# MKW38A4 register map
Vendor: NXP Semiconductors; Series: Kinetis_W; File version: 1.6
CPU: CM0PLUS r0p0, little endian, no MPU, no FPU, VTOR, 2 interrupt priority bits
Registers are 32-bit, read-write, no defined reset value unless marked. A register's access mark holds for its fields unless they carry their own. Offsets are from the block's base; [hi:lo] are bit positions; {n}, {i} and the like mark numbered series.

## GENFSK — GENERIC FSK
Base 0x40082000
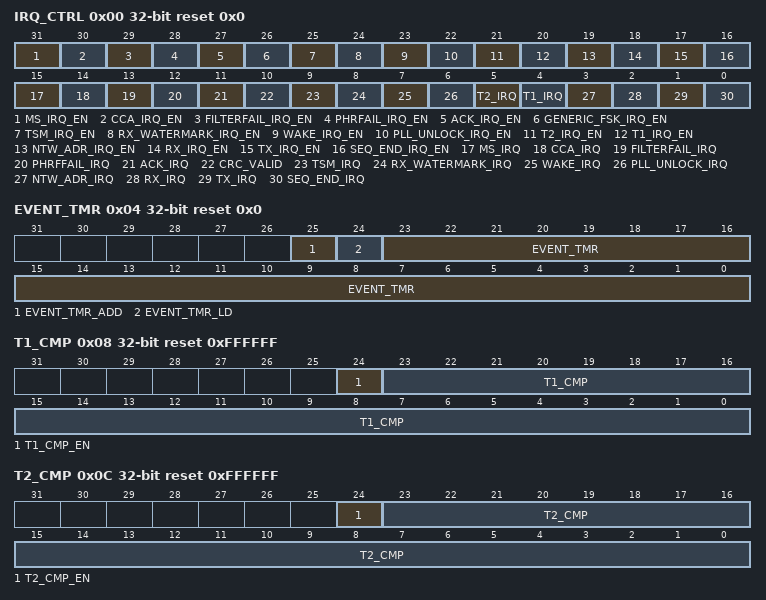
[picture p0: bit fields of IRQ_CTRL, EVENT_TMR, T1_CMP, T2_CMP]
0x00 IRQ_CTRL reset 0x0 — IRQ CONTROL
  [31] MS_IRQ_EN — MS_IRQ Enable
    0=MS Interrupt is not enabled; 1=MS Interrupt is enabled
  [30] CCA_IRQ_EN — CCA_IRQ Enable
    0=CCA Interrupt is not enabled; 1=CCA Interrupt is enabled
  [29] FILTERFAIL_IRQ_EN — FILTERFAIL_IRQ Enable
    0=FILTERFAIL Interrupt is not enabled; 1=FILTERFAIL Interrupt is enabled
  [28] PHRFAIL_IRQ_EN — PHRFAIL_IRQ Enable
    0=PHRFAIL Interrupt is not enabled; 1=PHRFAIL Interrupt is enabled
  [27] ACK_IRQ_EN — ACK_IRQ Enable
    0=Auto ACK Interrupt is not enabled; 1=Auto ACK Interrupt is enabled
  [26] GENERIC_FSK_IRQ_EN — GENERIC_FSK_IRQ Master Enable
    0=All GENERIC_FSK Interrupts are disabled; 1=All GENERIC_FSK Interrupts can be enabled
  [25] TSM_IRQ_EN — TSM_IRQ Enable
    0=TSM Interrupt is not enabled; 1=TSM Interrupt is enabled
  [24] RX_WATERMARK_IRQ_EN — RX_WATERMARK_IRQ Enable
    0=RX Watermark Interrupt is not enabled; 1=RX Watermark Interrupt is enabled
  [23] WAKE_IRQ_EN — WAKE_IRQ Enable
    0=Wake Interrupt is not enabled; 1=Wake Interrupt is enabled
  [22] PLL_UNLOCK_IRQ_EN — PLL_UNLOCK_IRQ Enable
    0=PLL Unlock Interrupt is not enabled; 1=PLL Unlock Interrupt is enabled
  [21] T2_IRQ_EN — T2_IRQ Enable
    0=Timer1 (T2) Compare Interrupt is not enabled; 1=Timer1 (T2) Compare Interrupt is enabled
  [20] T1_IRQ_EN — T1_IRQ Enable
    0=Timer1 (T1) Compare Interrupt is not enabled; 1=Timer1 (T1) Compare Interrupt is enabled
  [19] NTW_ADR_IRQ_EN — NTW_ADR_IRQ Enable
    0=Network Address Match Interrupt is not enabled; 1=Network Address Match Interrupt is enabled
  [18] RX_IRQ_EN — RX_IRQ Enable
    0=RX Interrupt is not enabled; 1=RX Interrupt is enabled
  [17] TX_IRQ_EN — TX_IRQ Enable
    0=TX Interrupt is not enabled; 1=TX Interrupt is enabled
  [16] SEQ_END_IRQ_EN — SEQ_END_IRQ Enable
    0=Sequence End Interrupt is not enabled; 1=Sequence End Interrupt is enabled
  [15] MS_IRQ — Mode Switch Interrupt
    0=A Mode Switch frame is not received; 1=A Mode Switch frame is received
  [14] CCA_IRQ — CCA Interrupt
    0=A CCA Interrupt has not occurred; 1=A CCA Interrupt has occurred
  [13] FILTERFAIL_IRQ — Received Frame Filter Fail Interrupt
    0=A Filter Fail Interrupt has not occurred; 1=A Filter Fail Interrupt has occurred
  [12] PHRFFAIL_IRQ — Received Frame PHR Fail Interrupt
    0=Received frame PHR Fail Interrupt is not asserted; 1=Received frame PHR Fail Interrupt is asserted
  [11] ACK_IRQ — Auto ACK Interrupt
    0=Auto ACK Interrupt is not asserted; 1=Auto ACK Interrupt is asserted
  [10] CRC_VALID ro
  [9] TSM_IRQ ro — TSM Interrupt
    0=TSM0_IRQ and TSM1_IRQ are both clear; 1=Indicates TSM0_IRQ or TSM1_IRQ is set in XCVR_STATUS
  [8] RX_WATERMARK_IRQ — RX Watermark Interrupt
    0=RX Watermark Interrupt is not asserted; 1=RX Watermark Interrupt is asserted
  [7] WAKE_IRQ — Wake Interrrupt
    0=Wake Interrupt is not asserted; 1=Wake Interrupt is asserted
  [6] PLL_UNLOCK_IRQ — PLL Unlock Interrupt
    0=PLL Unlock Interrupt is not asserted; 1=PLL Unlock Interrupt is asserted
  [5] T2_IRQ — Timer2 (T2) Compare Interrupt
    0=Timer2 (T2) Compare Interrupt is not asserted; 1=Timer2 (T2) Compare Interrupt is asserted
  [4] T1_IRQ — Timer1 (T1) Compare Interrupt
    0=Timer1 (T1) Compare Interrupt is not asserted; 1=Timer1 (T1) Compare Interrupt is asserted
  [3] NTW_ADR_IRQ — Network Address Match Interrupt
    0=Network Address Match Interrupt is not asserted; 1=Network Address Match Interrupt is asserted
  [2] RX_IRQ — RX Interrupt
    0=RX Interrupt is not asserted; 1=RX Interrupt is asserted
  [1] TX_IRQ — TX Interrupt
    0=TX Interrupt is not asserted; 1=TX Interrupt is asserted
  [0] SEQ_END_IRQ — Sequence End Interrupt
    0=Sequence End Interrupt is not asserted; 1=Sequence End Interrupt is asserted
0x04 EVENT_TMR reset 0x0 (reset mask 0xFF000000) — EVENT TIMER
  [25] EVENT_TMR_ADD wo — Event Timer Add
  [24] EVENT_TMR_LD wo — Event Timer Load
  [23:0] EVENT_TMR — Event Timer
0x08 T1_CMP reset 0xFFFFFF — T1 COMPARE
  [24] T1_CMP_EN — Timer1 (T1) Compare Enable
  [23:0] T1_CMP — Timer1 (T1) Compare Value
0x0C T2_CMP reset 0xFFFFFF — T2 COMPARE
  [24] T2_CMP_EN — Timer2 (T2) Compare Enable
  [23:0] T2_CMP — Timer2 (T2) Compare Value
0x10 TIMESTAMP ro reset 0x0 (reset mask 0xFF000000)
  [23:0] TIMESTAMP — Received Packet Timestamp
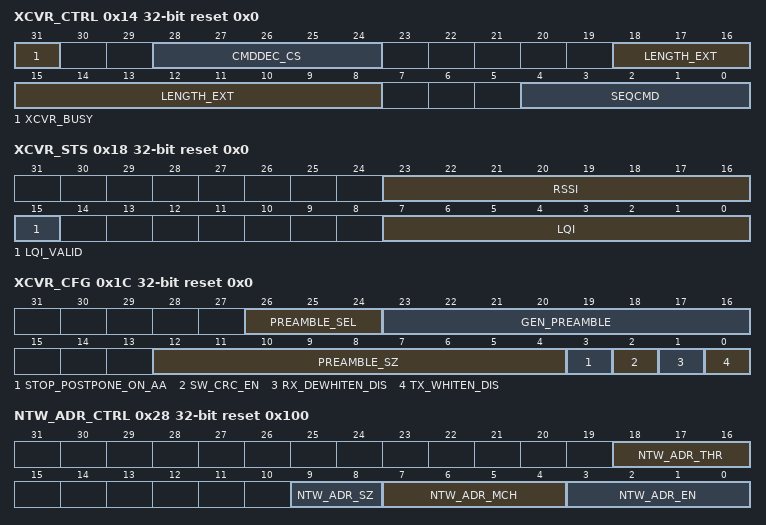
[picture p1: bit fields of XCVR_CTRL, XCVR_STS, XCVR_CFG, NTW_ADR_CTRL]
0x14 XCVR_CTRL reset 0x0 (reset mask 0x60F800FF) — TRANSCEIVER CONTROL
  [31] XCVR_BUSY ro — Transceiver Busy
    0=IDLE; 1=BUSY
  [28:24] CMDDEC_CS ro — Command Decode
  [18:8] LENGTH_EXT ro — Extracted Length Field
  [4:0] SEQCMD — Sequence Commands, also named as "XCVSEQ(Transceiver Sequence)"
    0=Same as command ABORT; 1=TX Start Now; 2=TX Start @ T1 Timer Compare Match (EVENT_TMR = T1_CMP); 3=TX Start @ T2 Timer Compare Match (EVENT_TMR = T2_CMP); 4=TX Cancel -- Cancels pending TX events but do not abort a TX-in-progress; 5=RX Start Now; 6=RX Start @ T1 Timer Compare Match (EVENT_TMR = T1_CMP); 7=RX Start @ T2 Timer Compare Match (EVENT_TMR = T2_CMP); 8=RX Stop @ T1 Timer Compare Match (EVENT_TMR = T1_CMP); 9=RX Stop @ T2 Timer Compare Match (EVENT_TMR = T2_CMP); 10=RX Cancel -- Cancels pending RX events but do not abort a RX-in-progress; 11=Abort All - Cancels all pending events and abort any sequence-in-progress; 12=TR Start Now; 13=TR Start @ T1 Timer Compare Match (EVENT_TMR = T1_CMP); 14=TR Start @ T2 Timer Compare Match (EVENT_TMR = T2_CMP); 15=TR Cancel -- Cancels pending TR events but do not abort a TR-in-progress; 16=CCA Start Now; 17=CCA Start @ T1 Timer Compare Match (EVENT_TMR = T1_CMP); 18=CCA Start @ T2 Timer Compare Match (EVENT_TMR = T2_CMP); 19=CCA Cancel -- Cancels pending CCA events but do not abort a CCA-in-progress
0x18 XCVR_STS ro reset 0x0 (reset mask 0xFF007F00) — TRANSCEIVER STATUS
  [23:16] RSSI — RSSI Value
  [15] LQI_VALID — LQI Valid Indicator
    0=LQI is not yet valid for RX packet; 1=LQI is valid for RX packet
  [7:0] LQI — Link Quality Indicator
0x1C XCVR_CFG reset 0x0 — TRANSCEIVER CONFIGURATION
  [26:24] PREAMBLE_SEL — Preamble Select
    0=The controller hardware selects the preamble pattern based on the first transmitted bit of Network Address, such that the last bit of preamble is the opposite polarity from the first bit of Network Address, forcing a bit transition at this boundary; 1=Preamble is programmed by register GEN_PREAMBLE[7:0]; 2=Preamble is 0b01; 3=Preamble is 0b10
  [23:16] GEN_PREAMBLE — Preamble pattern
  [12:4] PREAMBLE_SZ — Preamble Size
  [3] STOP_POSTPONE_ON_AA — Postpone Stop Command Timeout On Access Address Match Enable
    0=STOP Abort will occur on RX_STOP_T1 or RX_STOP_T1 Event Timer match, regardless of NTW_ADR_MCH; 1=STOP Abort will be deferred on RX_STOP_T1 or RX_STOP_T1 Event Timer match, if NTW_ADR_MCH is asserted; otherwise the RX_STOP Abort will occur immediately
  [2] SW_CRC_EN — Software CRC Enable
  [1] RX_DEWHITEN_DIS — RX De-Whitening Disable
  [0] TX_WHITEN_DIS — TX Whitening Disable
0x20 CHANNEL_NUM0 reset 0x0 — CHANNEL NUMBER 0
  [6:0] CHANNEL_NUM0 — Channel Number for PAN0
0x24 TX_POWER reset 0x0 — TRANSMIT POWER
  [5:0] TX_POWER — Transmit Power
0x28 NTW_ADR_CTRL reset 0x100 (reset mask 0xFFFFFF0F) — NETWORK ADDRESS CONTROL
  [18:16] NTW_ADR_THR — Network Address Threshold
  [9:8] NTW_ADR_SZ — Network Address Size
    0=Network Address 0/1/2/3 requires a 8-bit correlation; 1=Network Address 0/1/2/3 requires a 16-bit correlation; 2=Network Address 0/1/2/3 requires a 24-bit correlation; 3=Network Address 0/1/2/3 requires a 32-bit correlation
  [7:4] NTW_ADR_MCH ro — Network Address Match
    1=Network Address 0 has matched; 2=Network Address 1 has matched; 4=Network Address 2 has matched; 8=Network Address 3 has matched
  [3:0] NTW_ADR_EN — Network Address Enable
    1=Enable Network Address 0 for correlation; 2=Enable Network Address 1 for correlation; 4=Enable Network Address 2 for correlation; 8=Enable Network Address 3 for correlation
{0x2C+4i} NTW_ADR_{i} reset 0x55555555 (i=0..2) — NETWORK ADDRESS {i}
  [31:0] NTW_ADR_{i} — Network Address {i}
0x38 NTW_ADR_3 reset 0x55555555 — NETWORK ADDRESS 3
  [31:0] NTW_ADR_3 — Network Address 2
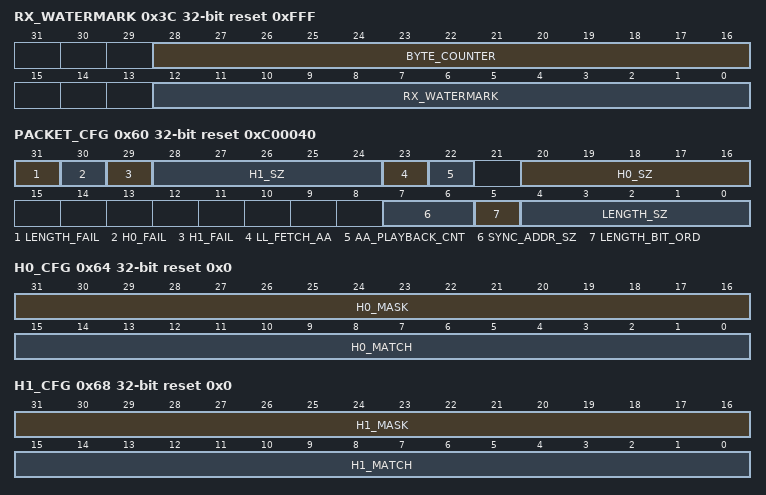
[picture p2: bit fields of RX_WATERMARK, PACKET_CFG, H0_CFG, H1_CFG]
0x3C RX_WATERMARK reset 0xFFF (reset mask 0xE000FFFF) — RECEIVE WATERMARK
  [28:16] BYTE_COUNTER ro
  [12:0] RX_WATERMARK — Receive Watermark
0x40 DSM_CTRL reset 0x0 — DSM CONTROL
  [0] GEN_SLEEP_REQUEST — GENERIC_FSK Deep Sleep Mode Request
0x44 PART_ID ro reset 0x2
  [7:0] PART_ID
0x48 SLOT_PRELOAD reset 0x2A8
  [15:0] SLOT_PRELOAD — Slotted Mode Preload
0x4C SLOT_TIME reset 0x8E8
  [15:0] SLOT_TIME — Duration of the Backoff Slot
0x50 TURNAROUND_TIME reset 0x3E8
  [15:0] TURNAROUND_TIME — RX-to-TX or TX-to-RX turnaround time
0x54 ACKDELAY reset 0x0
  [9:0] ACKDELAY
0x58 RXDELAY reset 0x0
  [9:0] RXDELAY
0x5C TXDELAY reset 0x0
  [9:0] TXDELAY
0x60 PACKET_CFG reset 0xC00040 (reset mask 0x1FFFFFFF) — PACKET CONFIGURATION
  [31] LENGTH_FAIL ro — Maximum Length Violated Status Bit
  [30] H0_FAIL ro — H0 Violated Status Bit
  [29] H1_FAIL ro — H1 Violated Status Bit
  [28:24] H1_SZ — H1 Size
  [23] LL_FETCH_AA — Link layer fetches AA from PHY
    0=Link layer does not fetch AA from PHY; 1=Link layer fetches AA from PHY when AA_PLAYBACK_CNT is 0
  [22] AA_PLAYBACK_CNT — AA PLAYBACK COUNT
    0=AA is not through CRC and not playback to Link layer; 1=AA is through CRC and palyback to Link Layer
  [20:16] H0_SZ — H0 Size
  [7:6] SYNC_ADDR_SZ — Sync Address Size
  [5] LENGTH_BIT_ORD — LENGTH Bit Order
    0=LS Bit First; 1=MS Bit First
  [4:0] LENGTH_SZ — LENGTH Size
0x64 H0_CFG reset 0x0 — H0 CONFIGURATION
  [31:16] H0_MASK, [15:0] H0_MATCH
0x68 H1_CFG reset 0x0 — H1 CONFIGURATION
  [31:16] H1_MASK, [15:0] H1_MATCH
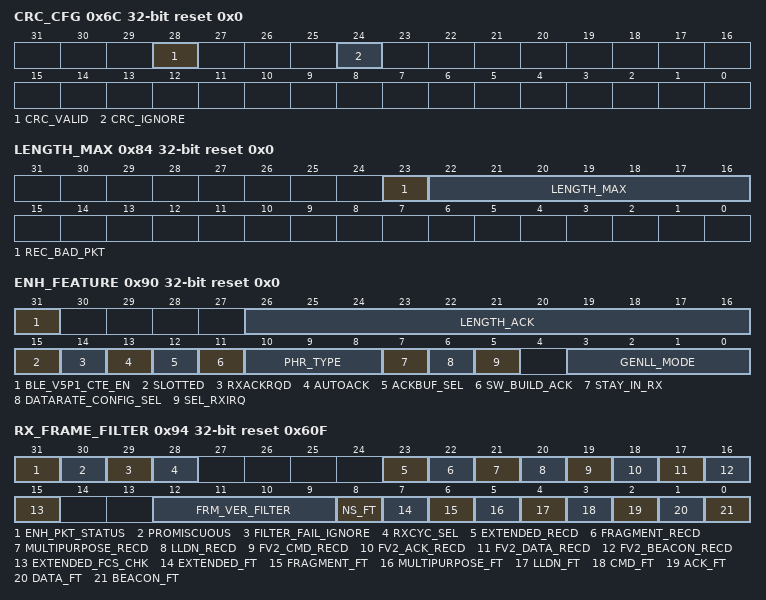
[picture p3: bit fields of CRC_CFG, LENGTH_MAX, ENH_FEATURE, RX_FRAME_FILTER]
0x6C CRC_CFG reset 0x0 (reset mask 0xFFFFFFF) — CRC CONFIGURATION
  [28] CRC_VALID ro
    0=CRC of RX packet is not valid; 1=CRC of RX packet is valid
  [24] CRC_IGNORE
    0=RX_IRQ will not be asserted for a received packet which fails CRC verification; 1=RX_IRQ will be asserted even for a received packet which fails CRC verification
0x70 LENGTH_ADJ reset 0x0 — LENGTH ADJUSTMENT
  [10:0] LENGTH_ADJ — Length Adjustment
0x84 LENGTH_MAX reset 0x0 — MAXIMUM LENGTH
  [23] REC_BAD_PKT — Receive Bad Packets
    0=packets which fail H0, H1, or LENGTH_MAX result in an automatic recycle after the header is received and parsed; 1=packets which fail H0, H1, or LENGTH_MAX are received in their entirety
  [22:16] LENGTH_MAX — Maximum Length for Received Packets
0x90 ENH_FEATURE reset 0x0 — ENHANCED FEATURES
  [31] BLE_V5P1_CTE_EN — Bluetooth LE version 5.1 CTE feature enable
    0=Do not support Bluetooth LE version 5.1 CTE feature; 1=Support Bluetooth LE version 5.1 CTE feature, which means the link layer hardware can parse the CTE field length and extend the RX_EN signal accordingly
  [26:16] LENGTH_ACK — Length of the ACK frame(or part of the ACK frame) in RAM
  [15] SLOTTED — Slotted Mode
  [14] RXACKRQD — Receive Acknowledge Frame required
    0=An ordinary receive frame (any type of frame) follows the transmit frame; 1=A receive Ack frame is expected to follow the transmit frame (non-Ack frames are rejected)
  [13] AUTOACK — Auto Acknowledge Enable
    0=sequence manager will not follow a receive frame with a Tx Ack frame, under any conditions; the autosequence will terminate after the receive frame; 1=sequence manager will follow a receive frame with an automatic hardware-generated Tx Ack frame, assuming other necessary conditions are met
  [12] ACKBUF_SEL — ACK frame is in 64-byte dedicated RAM or TX buffer RAM
    0=ACK frame is in 64-byte dedicated RAM; 1=ACK frame is in TX buffer RAM
  [11] SW_BUILD_ACK — Software builds the ACK packet in RAM
    0=Hardware builds part of or the whole of the auto ACK frame; 1=Software builds the whole auto ACK frame in RAM
  [10:8] PHR_TYPE
    0=The packet type is GFSK; 1=The packet type is MSK; 2=The packet type is SUN FSK; 3=The packet type is LECIM FSK
  [7] STAY_IN_RX — Stay in receive
    0=Linklayer will warmdown after an RX_IRQ; 1=Linklayer will recycle and stay in receive even after an RX_IRQ
  [6] DATARATE_CONFIG_SEL — Select the data rate configuration bank
    0=Select the data rate as per configuration bank 0; 1=Select the data rate as per configuration bank 1
  [5] SEL_RXIRQ — Select the RX IRQ assert time
    0=RX_IRQ is asserted at the end of RX_PKT state; 1=RX_IRQ is asserted at the end of RXEN_DLY state. This to be used for delaying RX_IRQ to accept TERM2 bits in Bluetooth LE-LR and CTE bits as needed.
  [3:0] GENLL_MODE — Linklayer Mode Select
    0=GLL Mode; 1=PAN Mode; 2=FAN Mode; 3=Hybrid Dual PAN Mode; 6=FCP Mode; 9=Bluetooth LE Uncoded Mode; 10=Bluetooth LE LR Mode; 11=Bluetooth LE Concurrent Mode (RX configuration only; TX uses either Bluetooth LE UNCODED or Bluetooth LE LR configuration); 15=GTM Mode
0x94 RX_FRAME_FILTER reset 0x60F (reset mask 0x7F00FFFF) — RECEIVE FRAME FILTER
  [31] ENH_PKT_STATUS ro — Enhanced Packet Status
    0=The last packet received was not 2015-compliant; 1=The last packet received was 2015-compliant (RX_FRAME_FILTER register should be queried for additional status bits)
  [30] PROMISCUOUS — Promiscuous Mode Enable
    0=normal mode; 1=all packet filtering except frame length checking (FrameLength>=5) is bypassed
  [29] FILTER_FAIL_IGNORE
    0=RX_IRQ will not be asserted when filter fail; 1=RX_IRQ will be asserted when filter fail
  [28] RXCYC_SEL — Rx Recycle Time Select
    0=Recycle when fail happens; 1=Recycle when Rx done and fail happens
  [23] EXTENDED_RECD ro — Extended Packet Received
    0=The last packet received was not Frame Type EXTENDED; 1=The last packet received was Frame Type EXTENDED, and EXTENDED_FT=1 to allow such packets
  [22] FRAGMENT_RECD ro — Fragment Packet Received
    0=last packet received was not Frame Type FRAGMENT; 1=The last packet received was Frame Type FRAGMENT, and FRAGMENT_FT=1 to allow such packets
  [21] MULTIPURPOSE_RECD ro — Multipurpose Packet Received
    0=last packet received was not Frame Type MULTIPURPOSE; 1=The last packet received was Frame Type MULTIPURPOSE, and MULTIPURPOSE_FT=1 to allow such packets
  [20] LLDN_RECD ro — LLDN Packet Received
    0=The last packet received was not Frame Type LLDN; 1=The last packet received was Frame Type LLDN, and LLDN_FT=1 to allow such packets
  [19] FV2_CMD_RECD ro — Frame Version 2 MAC Command Packet Received
    0=The last packet received was not Frame Type MAC Command with Frame Version 2; 1=The last packet received was Frame Type MAC Command with Frame Version 2, and FRM_VER_FILTER[2]=1 to allow such packets
  [18] FV2_ACK_RECD ro — Frame Version 2 Acknowledge Packet Received
    0=The last packet received was not Frame Type Ack with Frame Version 2; 1=The last packet received was Frame Type Ack with Frame Version 2, and FRM_VER_FILTER[2]=1 to allow such packets
  [17] FV2_DATA_RECD ro — Frame Version 2 Data Packet Received
    0=The last packet received was not Frame Type Data with Frame Version 2; 1=The last packet received was Frame Type Data with Frame Version 2, and FRM_VER_FILTER[2]=1 to allow such packets
  [16] FV2_BEACON_RECD ro — Frame Version 2 Beacon Packet Received
    0=The last packet received was not Frame Type Beacon with Frame Version 2; 1=The last packet received was Frame Type Beacon with Frame Version 2, and FRM_VER_FILTER[2]=1 to allow such packets
  [15] EXTENDED_FCS_CHK — Verify FCS on Frame Type Extended
    0=Packet Processor will not check FCS for Frame Type EXTENDED (default); 1=Packet Processor will check FCS at end-of-packet based on packet length derived from PHR, for Frame Type EXTENDED
  [12:9] FRM_VER_FILTER — Frame Version selector.
  [8] NS_FT — "Not Specified" Frame Type Enable
    0=reject all "Not Specified" frames; 1=Not-specified (reserved) frame type enabled. Applies to Frame Type 6. No packet filtering is performed, except for frame length checking (FrameLength>=5 and FrameLength<=127). No AUTOACK is transmitted for this Frame Type
  [7] EXTENDED_FT — Extended Frame Type Enable
    0=reject all Extended frames; 1=Extended frame type enabled (Frame Type 7)
  [6] FRAGMENT_FT — Fragment Frame Type Enable
    0=reject all Fragment frames; 1=Fragment frame type enabled (Frame Type 6)
  [5] MULTIPURPOSE_FT — Multipurpose Frame Type Enable
    0=reject all Multipurpose frames; 1=Multipurpose frame type enabled (Frame Type 5)
  [4] LLDN_FT — LLDN Frame Type Enable
    0=reject all LLDN frames; 1=LLDN frame type enabled (Frame Type 4)
  [3] CMD_FT — MAC Command Frame Type Enable
    0=reject all MAC Command frames; 1=MAC Command frame type enabled
  [2] ACK_FT — Ack Frame Type Enable
    0=reject all Acknowledge frames; 1=Acknowledge frame type enabled
  [1] DATA_FT — Data Frame Type Enable
    0=reject all Beacon frames; 1=Data frame type enabled
  [0] BEACON_FT — Beacon Frame Type Enable
    0=reject all Beacon frames; 1=Beacon frame type enabled
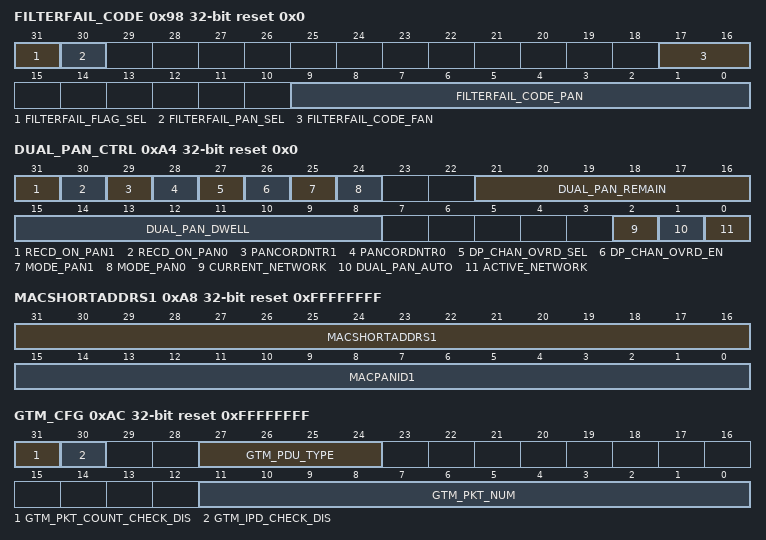
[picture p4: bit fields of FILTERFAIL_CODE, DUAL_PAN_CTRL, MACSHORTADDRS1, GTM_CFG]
0x98 FILTERFAIL_CODE reset 0x0 (reset mask 0x7FFCFC00)
  [31] FILTERFAIL_FLAG_SEL ro — Consolidated Filter Fail Flag
  [30] FILTERFAIL_PAN_SEL — PAN Selector for Filter Fail Code
    0=FILTERFAIL_CODE_PAN/FILTERFAIL_CODE_FAN will report the FILTERFAIL status of PAN0; 1=FILTERFAIL_CODE_PAN/FILTERFAIL_CODE_FAN will report the FILTERFAIL status of PAN1
  [17:16] FILTERFAIL_CODE_FAN ro — Filter Fail Code When in FAN Mode
  [9:0] FILTERFAIL_CODE_PAN ro — Filter Fail Code When in PAN Mode
0x9C LENIENCY_LSB reset 0x0
0xA0 LENIENCY_MSB reset 0x0
  [12:0] LENIENCY_MSB
0xA4 DUAL_PAN_CTRL reset 0x0 (reset mask 0x3FC0FFFB) — DUAL PAN CONTROL
  [31] RECD_ON_PAN1 ro — Last Packet was Received on PAN1
  [30] RECD_ON_PAN0 ro — Last Packet was Received on PAN0
  [29] PANCORDNTR1 — Device is a PAN Coordinator on PAN1
  [28] PANCORDNTR0 — Device is a PAN Coordinator on PAN0
  [27] DP_CHAN_OVRD_SEL — Dual PAN Channel Override Selector
  [26] DP_CHAN_OVRD_EN — Dual PAN Channel Override Enable
  [25] MODE_PAN1 — PAN1 Mode Select
    0=PAN1 is in PAN mode; 1=PAN1 is in FAN mode
  [24] MODE_PAN0 — PAN0 Mode Select
    0=PAN0 is in PAN mode; 1=PAN0 is in FAN mode
  [21:16] DUAL_PAN_REMAIN ro — Time Remaining before next PAN switch in auto Dual PAN mode
  [15:8] DUAL_PAN_DWELL — Dual PAN Channel Frequency Dwell Time
  [2] CURRENT_NETWORK ro — Indicates which PAN is currently selected by hardware
    0=PAN0 is selected; 1=PAN1 is selected
  [1] DUAL_PAN_AUTO — Activates automatic Dual PAN operating mode
  [0] ACTIVE_NETWORK — Active Network Selector
    0=Select PAN0; 1=Select PAN1
0xA8 GTM_PDU reset 0xFFFFFFFF (GENFSK view) — GTM MODE PDU
0xA8 MACSHORTADDRS1 reset 0xFFFFFFFF (GENFSK view) — MAC SHORT ADDRESS FOR PAN1
  [31:16] MACSHORTADDRS1 — MAC SHORT ADDRESS for PAN1
  [15:0] MACPANID1 — MAC PAN ID for PAN1
0xAC GTM_CFG reset 0xFFFFFFFF (GENFSK view) — GTM MODE CONFIGURATION
  [31] GTM_PKT_COUNT_CHECK_DIS — GTM MODE PACKET NUMBER CHECK DISABLE
  [30] GTM_IPD_CHECK_DIS — GTM MODE INTER-PACKET DURATION CHECK DISABLE
  [27:24] GTM_PDU_TYPE — GTM MODE PDU TYPE SELECTION
    0=PRBS9 Sequence; 1=Programmable 8-bit Pattern (from register GTM_PDU[7:0], reused from MACSHORTADDRS1[7:0]); 2=PRBS-13 Sequence; 3=PRBS-15 Sequence; 4=Programmable 32-bit Pattern (from register GTM_PDU[31:0], reused from {MACSHORTADDRS1,MACPANID1}); 5=Programmable packet from Packet RAM (in this case, PKT_LEN is ignored)
  [11:0] GTM_PKT_NUM — GTM MODE PACKET NUMBER
0xAC MACLONGADDRS1_LSB reset 0xFFFFFFFF (GENFSK view) — MAC LONG ADDRESS 1 LSB
  [31:0] MACLONGADDRS1_LSB — MAC LONG ADDRESS for PAN1 LSB
0xB0 GTM_IPD reset 0xFFFFFFFF (GENFSK view) — GTM MODE INTER-PACKET DURATION
  [19:0] GTM_IPD
0xB0 MACLONGADDRS1_MSB reset 0xFFFFFFFF (GENFSK view) — MAC LONG ADDRESS 1 MSB
  [31:0] MACLONGADDRS1_MSB — MAC LONG ADDRESS for PAN1 MSB
0xB4 CHANNEL_NUM1 reset 0x0 — CHANNEL NUMBER 1
  [6:0] CHANNEL_NUM1 — Channel Number for PAN1
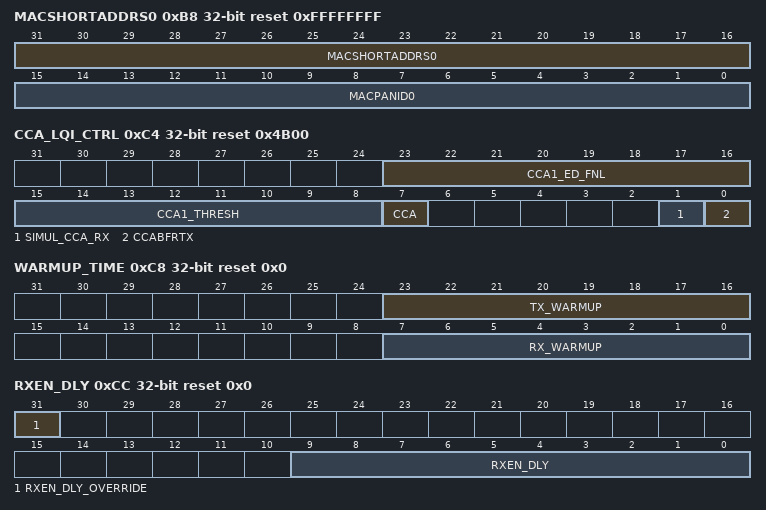
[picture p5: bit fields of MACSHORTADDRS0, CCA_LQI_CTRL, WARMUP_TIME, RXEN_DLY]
0xB8 MACSHORTADDRS0 reset 0xFFFFFFFF — MAC SHORT ADDRESS 0
  [31:16] MACSHORTADDRS0 — MAC SHORT ADDRESS FOR PAN0
  [15:0] MACPANID0 — MAC PAN ID for PAN0
0xBC GTM_FIRST_SFD2WD reset 0xFFFFFFFF (GENFSK view) — GTM MODE TIME OF FIRST SFD FOUND TO FORCE RX WARMDOWN
  [19:0] GTM_FIRST_SFD2WD
0xBC MACLONGADDRS0_LSB reset 0xFFFFFFFF (GENFSK view) — MAC LONG ADDRESS 0 LSB
  [31:0] MACLONGADDRS0_LSB — MAC LONG ADDRESS for PAN0 LSB
0xC0 GTM_RX_RECYCLE_TIME reset 0xFFFFFFFF (GENFSK view) — GTM MODE RX RECYCLE TIME
  [19:0] GTM_RX_RECYCLE_TIME
0xC0 MACLONGADDRS0_MSB reset 0xFFFFFFFF (GENFSK view) — MAC LONG ADDRESS 0 MSB
  [31:0] MACLONGADDRS0_MSB — MAC LONG ADDRESS for PAN0 MSB
0xC4 CCA_LQI_CTRL reset 0x4B00 (reset mask 0xFF00FF7F) — CCA AND LQI CONTROL
  [23:16] CCA1_ED_FNL ro — Final Result for CCA Mode 1 and Energy Detect
  [15:8] CCA1_THRESH — CCA Mode 1 Threshold
  [7] CCA ro — CCA Status
    0=IDLE; 1=BUSY
  [1] SIMUL_CCA_RX — Simultaneous CCA and Receive Enable
    0=Packets can't be received during CCA measurement; 1=Packet reception is enabled during CCA measurement if preamble and SFD are detected
  [0] CCABFRTX — CCA Before TX
    0=no CCA required, transmit operation begins immediately; 1=at least one CCA measurement is required prior to the transmit operation (see also SLOTTED)
0xC8 WARMUP_TIME ro reset 0x0 (reset mask 0xFF00FF00) — TX/RX WARMUP TIME
  [23:16] TX_WARMUP — Transmit Warmup Time
  [7:0] RX_WARMUP — Receive Warmup Time
0xCC RXEN_DLY reset 0x0 — RX_EN Delay Time
  [31] RXEN_DLY_OVERRIDE — RX_EN delay to de-assert time override enable.
    0=For Bluetooth LE case, RX_EN signal will delay to de-assert accroding to the length of TERM2 or CTE(when BLE_V5P1_CTE_EN is enabled) field parsed by hardware; 1=For all receive case, RX_EN signal will delay to de-assert accroding to register RXEN_DLY[9:0]
  [9:0] RXEN_DLY — When RXEN_DLY is not zero, the RX_EN signal will delay (RXEN_DLY +1) microseconds to de-assert after packet is received
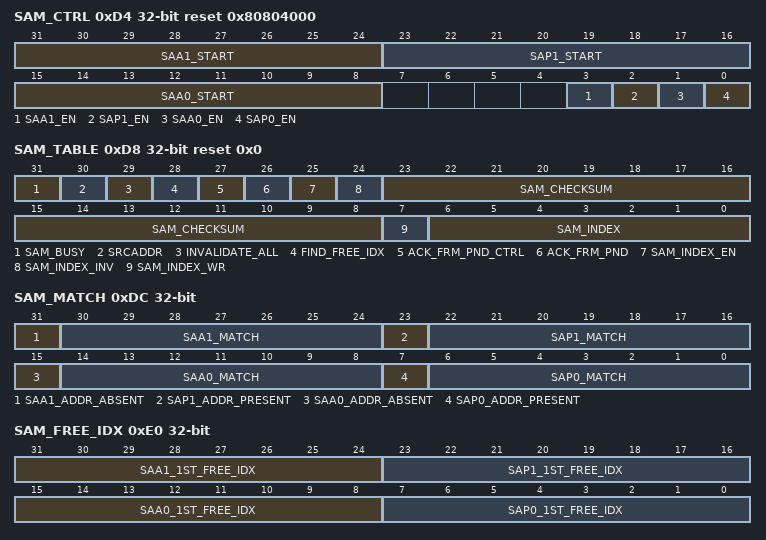
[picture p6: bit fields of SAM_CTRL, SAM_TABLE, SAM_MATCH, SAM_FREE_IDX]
0xD4 SAM_CTRL reset 0x80804000 — SAM CONTROL
  [31:24] SAA1_START — First Index of SAA1 partition
  [23:16] SAP1_START — First Index of SAP1 partition
  [15:8] SAA0_START — First Index of SAA0 partition
  [3] SAA1_EN — Enables SAA1 Partition of the SAM Table
    0=Disables SAA1 Partition; 1=Enables SAA1 Partition
  [2] SAP1_EN — Enables SAP1 Partition of the SAM Table
    0=Disables SAP1 Partition; 1=Enables SAP1 Partition
  [1] SAA0_EN — Enables SAA0 Partition of the SAM Table
    0=Disables SAA0 Partition; 1=Enables SAA0 Partition
  [0] SAP0_EN — Enables SAP0 Partition of the SAM Table
    0=Disables SAP0 Partition; 1=Enables SAP0 Partition
0xD8 SAM_TABLE reset 0x0 (reset mask 0xC00007F) — SOURCE ADDRESS MANAGEMENT TABLE
  [31] SAM_BUSY ro — SAM Table Update Status Bit
  [30] SRCADDR ro — Source Address Match Status
  [29] INVALIDATE_ALL wo — Invalidate Entire SAM Table
  [28] FIND_FREE_IDX wo — Find First Free Index
  [27] ACK_FRM_PND_CTRL — Manual Control for AutoTxAck FramePending field
    0=the FramePending field of the Frame Control Field of the next automatic TX acknowledge packet is determined by hardware; 1=the FramePending field of the Frame Control Field of the next automatic TX acknowledge packet tracks ACK_FRM_PEND
  [26] ACK_FRM_PND — State of AutoTxAck FramePending field when SAM Accelleration is Disabled
  [25] SAM_INDEX_EN wo — Enable the SAM table index selected by SAM_INDEX
  [24] SAM_INDEX_INV wo — Invalidate the SAM table index selected by SAM_INDEX
  [23:8] SAM_CHECKSUM — Software-computed source address checksum, to be installed into a table index
  [7] SAM_INDEX_WR wo — Enables SAM Table Contents to be updated
  [6:0] SAM_INDEX — Contains the SAM table index to be enabled or invalidated
0xDC SAM_MATCH ro — SOURCE ADDRESS MANAGEMENT MATCH
  [31] SAA1_ADDR_ABSENT — A Checksum Match is Absent in the SAP1 Partition of the SAM Table
  [30:24] SAA1_MATCH — Index in the SAA1 Partition of the SAM Table corresponding to the first checksum match
  [23] SAP1_ADDR_PRESENT — A Checksum Match is Present in the SAP1 Partition of the SAM Table
  [22:16] SAP1_MATCH — Index in the SAP1 Partition of the SAM Table corresponding to the first checksum match
  [15] SAA0_ADDR_ABSENT — A Checksum Match is Absent in the SAA0 Partition of the SAM Table
  [14:8] SAA0_MATCH — Index in the SAA0 Partition of the SAM Table corresponding to the first checksum match
  [7] SAP0_ADDR_PRESENT — A Checksum Match is Present in the SAP0 Partition of the SAM Table
  [6:0] SAP0_MATCH — Index in the SAP0 Partition of the SAM Table corresponding to the first checksum match
0xE0 SAM_FREE_IDX ro — SAM FREE INDEX
  [31:24] SAA1_1ST_FREE_IDX — First non-enabled (invalid) index in the SAA1 partition
  [23:16] SAP1_1ST_FREE_IDX — First non-enabled (invalid) index in the SAP1 partition
  [15:8] SAA0_1ST_FREE_IDX — First non-enabled (invalid) index in the SAA0 partition
  [7:0] SAP0_1ST_FREE_IDX — First non-enabled (invalid) index in the SAP0 partition
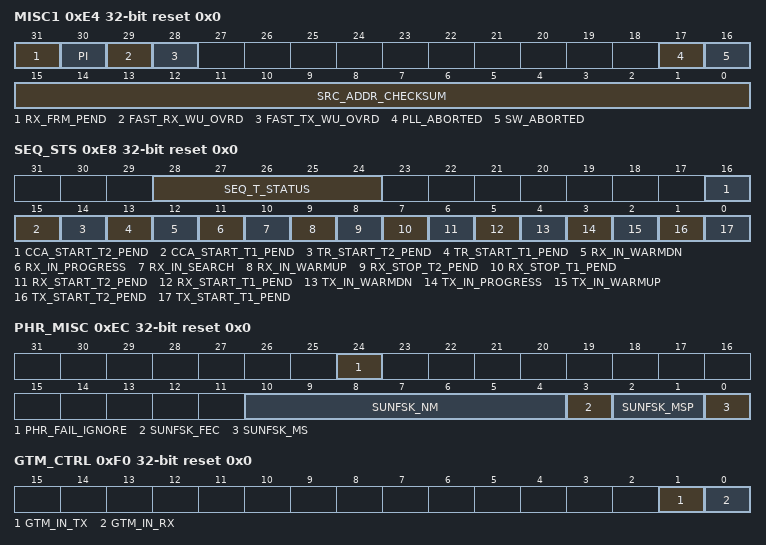
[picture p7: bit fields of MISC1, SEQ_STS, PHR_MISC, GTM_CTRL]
0xE4 MISC1 reset 0x0 (reset mask 0x3FFC0000) — MISCELLANEOUS(1)
  [31] RX_FRM_PEND ro — RX Frame Pending
  [30] PI ro — Poll Indication
    0=the received packet was not a data request; 1=the received packet was a data request, regardless of whether a Source Address table match occurred, or whether Source Address Management is enabled or not
  [29] FAST_RX_WU_OVRD — FAST_RX_WU override
    0=If TSM enables Fast Warmup Capability, LL will request it when RX in TR; 1=If TSM enables Fast Warmup Capability, LL will request it at every RX. User should insure channel is not changed since last sequence.
  [28] FAST_TX_WU_OVRD — FAST_TX_WU override
    0=If TSM enables Fast Warmup Capability, LL will request it when TX in RT or (CCA+TX); 1=If TSM enables Fast Warmup Capability, LL will request it at every TX. User should insure channel is not changed since last sequence.
  [17] PLL_ABORTED ro — Autosequence has terminated due to an PLL unlock event.
  [16] SW_ABORTED ro — Autosequence has terminated due to a Software abort.
  [15:0] SRC_ADDR_CHECKSUM ro — Hardware-computed received source address checksum
0xE8 SEQ_STS ro reset 0x0 (reset mask 0xE0FFFFFF) — SEQUENCE STATUS
  [28:24] SEQ_T_STATUS — Status of the just-completed or ongoing Sequence T or Sequence TR
  [16] CCA_START_T2_PEND — CCA T2 Start Pending Status
  [15] CCA_START_T1_PEND — CCA T1 Start Pending Status
  [14] TR_START_T2_PEND — TR T2 Start Pending Status
  [13] TR_START_T1_PEND — TR T1 Start Pending Status
  [12] RX_IN_WARMDN — RX Warmdown Status
  [11] RX_IN_PROGRESS — RX in Progress Status
  [10] RX_IN_SEARCH — RX Search Status
  [9] RX_IN_WARMUP — RX Warmup Status
  [8] RX_STOP_T2_PEND — RX T2 Start Pending Status
  [7] RX_STOP_T1_PEND — RX T1 Stop Pending Status
  [6] RX_START_T2_PEND — RX T2 Start Pending Status
  [5] RX_START_T1_PEND — RX T1 Start Pending Status
  [4] TX_IN_WARMDN — TX Warmdown Status
  [3] TX_IN_PROGRESS — TX in Progress Status
  [2] TX_IN_WARMUP — TX Warmup Status
  [1] TX_START_T2_PEND — TX T2 Start Pending Status
  [0] TX_START_T1_PEND — TX T1 Start Pending Status
0xEC PHR_MISC reset 0x0 — PHR MISCELLANEOUS
  [24] PHR_FAIL_IGNORE — Ignore PHR Fail
  [10:4] SUNFSK_NM ro — New Mode Bit
  [3] SUNFSK_FEC ro — New Mode FEC Bit
  [2:1] SUNFSK_MSP ro — Mode Switch Parameter Bit
  [0] SUNFSK_MS ro — Mode Switch Bit
0xF0 GTM_CTRL reset 0x0 — GTM CONTROL
  [1] GTM_IN_TX — Enable GTM Transmit Mode
    0=GTM transmit mode is not enabled; 1=GTM transmit mode is enabled
  [0] GTM_IN_RX — Enable GTM Receive Mode
    0=GTM receive mode is not enabled; 1=GTM receive mode is enabled
0xF4 GTM_BAD_CNT ro reset 0x0 — GTM BAD PACKET COUNTER
  [11:0] GTM_BAD_PKT_COUNT — GTM Bad Packet Counter
0xF8 GTM_GOOD_CNT ro reset 0x0 — GTM GOOD PACKET COUNTER
  [11:0] GTM_GOOD_PKT_COUNT — GTM Good Packet Counter
0xFC GTM_PKT_CNT ro reset 0x0 — GTM PACKET COUNTER
  [12:0] GTM_PKT_COUNT — GTM Packet Counter
